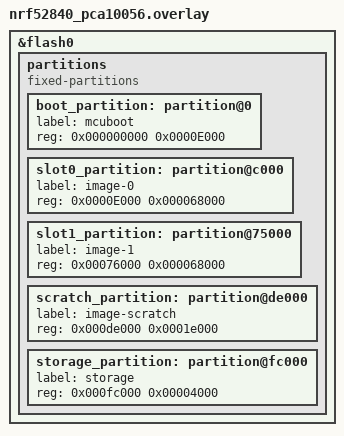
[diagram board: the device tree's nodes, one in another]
/* Copyright (c) 2019 Nordic Semiconductor ASA
 *
 * SPDX-License-Identifier: Apache-2.0
 */

&flash0 {
	/*
	 * For more information, see:
	 * http://docs.zephyrproject.org/latest/guides/dts/index.html#flash-partitions
	 */

	partitions {
		compatible = "fixed-partitions";
		#address-cells = <1>;
		#size-cells = <1>;

		boot_partition: partition@0 {
			label = "mcuboot";
			reg = <0x000000000 0x0000E000>;
		};
		slot0_partition: partition@c000 {
			label = "image-0";
			reg = <0x0000E000 0x000068000>;
		};
		slot1_partition: partition@75000 {
			label = "image-1";
			reg = <0x00076000 0x000068000>;
		};
		scratch_partition: partition@de000 {
			label = "image-scratch";
			reg = <0x000de000 0x0001e000>;
		};
		storage_partition: partition@fc000 {
			label = "storage";
			reg = <0x000fc000 0x00004000>;
		};
	};
};
